AUTOSAR XML (schema 00052)
package /katech/AdaptiveApplicationSwComponentTypes
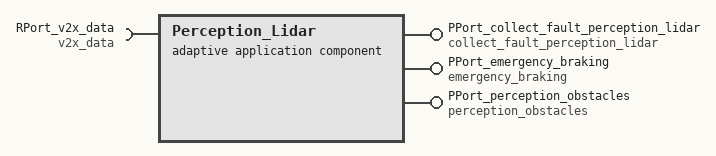
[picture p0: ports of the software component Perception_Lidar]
  adaptive application sw component type Perception_Lidar
    provide port PPort_collect_fault_perception_lidar: provided-interface=collect_fault_perception_lidar
    provide port PPort_emergency_braking: provided-interface=emergency_braking
    provide port PPort_perception_obstacles: provided-interface=perception_obstacles
    require port RPort_v2x_data: required-interface=v2x_data
package /katech/Executables
  executable Perception_Lidar: category=APPLICATION_LEVEL, minimum-timer-granularity=1000
    root sw component prototype Perception_Lidar: application-type=Perception_Lidar
